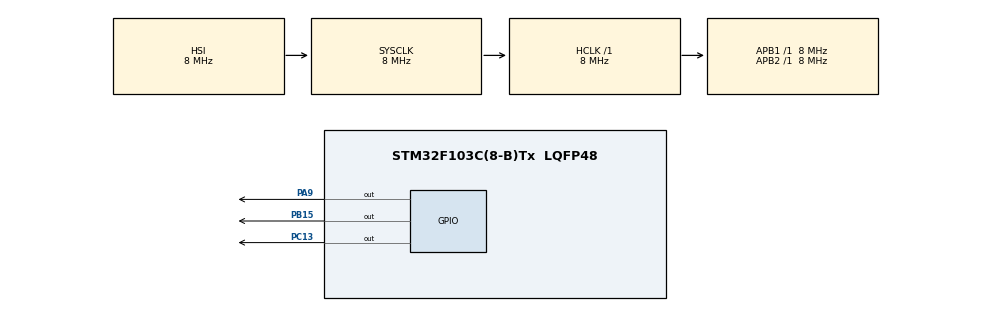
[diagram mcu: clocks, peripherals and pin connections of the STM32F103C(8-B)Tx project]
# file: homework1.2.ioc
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Mcu.Family=STM32F1
Mcu.Name=STM32F103C(8-B)Tx
Mcu.Package=LQFP48
NVIC.PriorityGroup=NVIC_PRIORITYGROUP_4
NVIC.TIM1_UP_IRQn=true\:0\:0\:false\:false\:true\:true\:true\:true
PA13.Mode=Serial_Wire
PA13.Signal=SYS_JTMS-SWDIO
PA14.Mode=Serial_Wire
PA14.Signal=SYS_JTCK-SWCLK
PA9.Signal=GPIO_Output
PB15.GPIO_ModeDefaultOutputPP=GPIO_MODE_OUTPUT_PP
PB15.GPIO_PuPd=GPIO_NOPULL
PB15.Signal=GPIO_Output
PC13-TAMPER-RTC.GPIO_ModeDefaultOutputPP=GPIO_MODE_OUTPUT_OD
PC13-TAMPER-RTC.GPIO_PuPd=GPIO_NOPULL
PC13-TAMPER-RTC.PinState=GPIO_PIN_SET
PC13-TAMPER-RTC.Signal=GPIO_Output
PD0-OSC_IN.Mode=HSE-External-Oscillator
PD0-OSC_IN.Signal=RCC_OSC_IN
PD1-OSC_OUT.Mode=HSE-External-Oscillator
PD1-OSC_OUT.Signal=RCC_OSC_OUT
ProjectManager.HeapSize=0x200
ProjectManager.StackSize=0x400
ProjectManager.TargetToolchain=MDK-ARM V5.32
RCC.AHBFreq_Value=8000000
RCC.APB1Freq_Value=8000000
RCC.APB1TimFreq_Value=8000000
RCC.APB2Freq_Value=8000000
RCC.APB2TimFreq_Value=8000000
RCC.HCLKFreq_Value=8000000
RCC.SYSCLKFreq_VALUE=8000000
RCC.USBFreq_Value=8000000
TIM1.AutoReloadPreload=TIM_AUTORELOAD_PRELOAD_ENABLE
TIM1.Period=999
TIM1.Prescaler=7
VP_TIM1_VS_ClockSourceINT.Mode=Internal
board=custom

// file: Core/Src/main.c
/* USER CODE BEGIN Header */
/**
  ******************************************************************************
  * @file           : main.c
  * @brief          : Main program body
  ******************************************************************************
  * @attention
  *
  * Copyright (c) 2026 STMicroelectronics.
  * All rights reserved.
  *
  * This software is licensed under terms that can be found in the LICENSE file
  * in the root directory of this software component.
  * If no LICENSE file comes with this software, it is provided AS-IS.
  *
  ******************************************************************************
  */
/* USER CODE END Header */
#include "main.h"
#include "tim.h"
#include "gpio.h"

/* USER CODE BEGIN PV */
static volatile uint32_t currentMiliSeconds = 0;
uint32_t led_tick = 0;
/* USER CODE END PV */

void SystemClock_Config(void);
/* USER CODE BEGIN PFP */
//static void MX_GPIO_Init(void);
//static void MX_TIM1_Init(void);
static uint32_t MyGetTick(void);
/* USER CODE END PFP */

/* USER CODE BEGIN 0 */
static uint32_t MyGetTick(void){
	return currentMiliSeconds;
	}
void HAL_TIM_PeriodElapsedCallback(TIM_HandleTypeDef *htim){
	if(htim == &htim1){
		currentMiliSeconds++;
	}
}
/* USER CODE END 0 */

int main(void)
{

  /* MCU Configuration--------------------------------------------------------*/

  /* Reset of all peripherals, Initializes the Flash interface and the Systick. */
  HAL_Init();

  /* Configure the system clock */
  SystemClock_Config();

  /* Initialize all configured peripherals */
  MX_GPIO_Init();
  MX_TIM1_Init();

  /* Infinite loop */
  /* USER CODE BEGIN WHILE */
	HAL_TIM_Base_Start_IT(&htim1);
  while (1)
  {
		if( MyGetTick()-led_tick >= 250 ){
        led_tick = MyGetTick();
        HAL_GPIO_TogglePin(GPIOA, GPIO_PIN_9);
			  //HAL_GPIO_TogglePin(GPIOC, GPIO_PIN_13);
    }
    /* USER CODE END WHILE */

  }
}

void SystemClock_Config(void)
{
  RCC_OscInitTypeDef RCC_OscInitStruct = {0};
  RCC_ClkInitTypeDef RCC_ClkInitStruct = {0};

  /** Initializes the RCC Oscillators according to the specified parameters
  * in the RCC_OscInitTypeDef structure.
  */
  RCC_OscInitStruct.OscillatorType = RCC_OSCILLATORTYPE_HSI;
  RCC_OscInitStruct.HSIState = RCC_HSI_ON;
  RCC_OscInitStruct.HSICalibrationValue = RCC_HSICALIBRATION_DEFAULT;
  RCC_OscInitStruct.PLL.PLLState = RCC_PLL_NONE;
  if (HAL_RCC_OscConfig(&RCC_OscInitStruct) != HAL_OK)
  {
    Error_Handler();
  }

  /** Initializes the CPU, AHB and APB buses clocks
  */
  RCC_ClkInitStruct.ClockType = RCC_CLOCKTYPE_HCLK|RCC_CLOCKTYPE_SYSCLK
                              |RCC_CLOCKTYPE_PCLK1|RCC_CLOCKTYPE_PCLK2;
  RCC_ClkInitStruct.SYSCLKSource = RCC_SYSCLKSOURCE_HSI;
  RCC_ClkInitStruct.AHBCLKDivider = RCC_SYSCLK_DIV1;
  RCC_ClkInitStruct.APB1CLKDivider = RCC_HCLK_DIV1;
  RCC_ClkInitStruct.APB2CLKDivider = RCC_HCLK_DIV1;

  if (HAL_RCC_ClockConfig(&RCC_ClkInitStruct, FLASH_LATENCY_0) != HAL_OK)
  {
    Error_Handler();
  }
}

void Error_Handler(void)
{
  __disable_irq();
  while (1)
  {
  }
}
